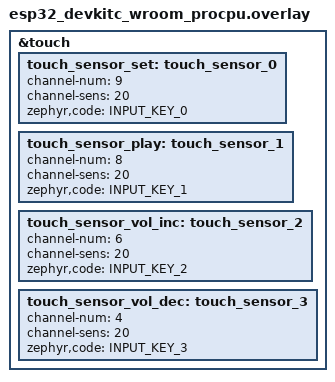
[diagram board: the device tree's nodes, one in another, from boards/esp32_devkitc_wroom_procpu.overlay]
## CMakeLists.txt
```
# SPDX-License-Identifier: Apache-2.0

cmake_minimum_required(VERSION 3.28.0)
find_package(Zephyr REQUIRED HINTS $ENV{ZEPHYR_BASE})
project(input_dump)

target_sources(app PRIVATE src/main.c)

target_sources_ifdef(CONFIG_USB_HOST_STACK app PRIVATE src/usbh_init.c)
```

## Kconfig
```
# Copyright 2023 Google LLC
# SPDX-License-Identifier: Apache-2.0

configdefault INPUT_SHELL
	default y

configdefault INPUT_SHELL_KBD_MATRIX_STATE
	default y

source "Kconfig.zephyr"
```

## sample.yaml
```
sample:
  name: Input Dump
common:
  tags: input
  build_only: true
  integration_platforms:
    - native_sim
tests:
  sample.input.input_dump: {}
  sample.input.input_dump_shell:
    extra_configs:
      - CONFIG_SHELL=y
```

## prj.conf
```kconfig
CONFIG_LOG=y
CONFIG_LOG_MODE_MINIMAL=y

CONFIG_INPUT=y
CONFIG_INPUT_EVENT_DUMP=y
```

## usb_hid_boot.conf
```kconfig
# Copyright (c) 2026 Antmicro <www.antmicro.com>
#
# SPDX-License-Identifier: Apache-2.0

CONFIG_USB_HOST_STACK=y
CONFIG_USBH_HID_BOOT_CLASS=y
CONFIG_USBH_HID_BOOT_INSTANCES_COUNT=1
```

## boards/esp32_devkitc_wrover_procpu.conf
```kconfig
CONFIG_INPUT_ESP32_TOUCH_SENSOR=y
```

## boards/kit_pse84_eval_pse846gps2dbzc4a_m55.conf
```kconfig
# SPDX-FileCopyrightText: Copyright (c) 2026 Infineon Technologies AG,
# SPDX-FileCopyrightText: or an affiliate of Infineon Technologies AG. All rights reserved.
#
# SPDX-License-Identifier: Apache-2.0

CONFIG_INPUT_FT5336_PERIOD_MS=20
CONFIG_INPUT_FT5336_INIT_DELAY_MS=1000
```

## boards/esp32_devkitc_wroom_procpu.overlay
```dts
/*
 * Copyright (c) 2023 Espressif Systems (Shanghai) Co., Ltd.
 *
 * SPDX-License-Identifier: Apache-2.0
 */

#include <zephyr/dt-bindings/input/input-event-codes.h>
#include <zephyr/dt-bindings/input/esp32-touch-sensor-input.h>

&touch {
	status = "okay";

	touch_sensor_set: touch_sensor_0 {
		channel-num = <9>;
		channel-sens = <20>;
		zephyr,code = <INPUT_KEY_0>;
	};

	touch_sensor_play: touch_sensor_1 {
		channel-num = <8>;
		channel-sens = <20>;
		zephyr,code = <INPUT_KEY_1>;
	};

	touch_sensor_vol_inc: touch_sensor_2 {
		channel-num = <6>;
		channel-sens = <20>;
		zephyr,code = <INPUT_KEY_2>;
	};

	touch_sensor_vol_dec: touch_sensor_3 {
		channel-num = <4>;
		channel-sens = <20>;
		zephyr,code = <INPUT_KEY_3>;
	};
};
```

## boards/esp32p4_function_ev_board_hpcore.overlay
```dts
/*
 * Copyright (c) 2026 Espressif Systems (Shanghai) Co., Ltd.
 *
 * SPDX-License-Identifier: Apache-2.0
 */

#include <zephyr/dt-bindings/input/input-event-codes.h>

&touch {
	status = "okay";

	touch_sensor_0 {
		channel-num = <1>;
		channel-sens = <2>;
		zephyr,code = <INPUT_KEY_0>;
	};

	touch_sensor_1 {
		channel-num = <2>;
		channel-sens = <2>;
		zephyr,code = <INPUT_KEY_1>;
	};

	touch_sensor_2 {
		channel-num = <3>;
		channel-sens = <2>;
		zephyr,code = <INPUT_KEY_2>;
	};

	touch_sensor_3 {
		channel-num = <4>;
		channel-sens = <2>;
		zephyr,code = <INPUT_KEY_3>;
	};
};
```

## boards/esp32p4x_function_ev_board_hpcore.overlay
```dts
/*
 * Copyright (c) 2026 Espressif Systems (Shanghai) Co., Ltd.
 *
 * SPDX-License-Identifier: Apache-2.0
 */

#include "esp32p4_function_ev_board_hpcore.overlay"
```

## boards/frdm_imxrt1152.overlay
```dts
/*
 * SPDX-FileCopyrightText: Copyright 2026 NXP
 *
 * SPDX-License-Identifier: Apache-2.0
 */

/*
 * 2x2 key matrix on J11, as in the MCUXpresso SDK kpp example:
 * ROW2 J11-8, ROW3 J11-12, COL2 J11-10, COL3 J11-6.
 */
&pinctrl {
	kpp_default: kpp_default {
		group0 {
			pinmux = <&iomuxc_gpio_ad_30_kpp_row02>,
				 <&iomuxc_gpio_ad_28_kpp_row03>,
				 <&iomuxc_gpio_ad_31_kpp_col02>,
				 <&iomuxc_gpio_ad_29_kpp_col03>;
			drive-strength = "high";
			bias-pull-up;
			slew-rate = "fast";
		};
	};
};

&kpp {
	pinctrl-0 = <&kpp_default>;
	pinctrl-names = "default";
	status = "okay";
};
```

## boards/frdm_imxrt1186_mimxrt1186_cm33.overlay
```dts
/*
 * SPDX-FileCopyrightText: Copyright 2026 NXP
 * SPDX-License-Identifier: Apache-2.0
 *
 * External 2x2 keypad wiring on FRDM-IMXRT1186 Arduino headers:
 *
 *   Keypad term    SoC pin         Arduino socket    KPP signal
 *   -----------    -------------   --------------    ----------
 *   R1             GPIO_EMC_B1_14  J1-10             KPP_ROW0
 *   R2             GPIO_AD_16      J51-4             KPP_ROW5
 *   C1             GPIO_EMC_B1_15  J1-12             KPP_COL0
 *   C2             GPIO_AD_17      J51-6             KPP_COL5
 *
 * Required jumper settings (default is ECAT route, switch to Arduino):
 *   J28 = 2-3  (route GPIO_AD_16 to Arduino J51-4)
 *   J32 = 2-3  (route GPIO_AD_17 to Arduino J51-6)
 */

&pinctrl {
	kpp_default: kpp_default {
		group0 {
			pinmux = <&iomuxc_gpio_ad_16_kpp_row5>,
				 <&iomuxc_gpio_emc_b1_14_kpp_row0>,
				 <&iomuxc_gpio_ad_17_kpp_col5>,
				 <&iomuxc_gpio_emc_b1_15_kpp_col0>;
			drive-strength = "high";
			bias-pull-up;
			slew-rate = "fast";
		};
	};
};

&kpp {
	pinctrl-0 = <&kpp_default>;
	pinctrl-names = "default";
	status = "okay";
};
```

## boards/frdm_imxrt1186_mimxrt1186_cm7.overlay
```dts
/*
 * SPDX-FileCopyrightText: Copyright 2026 NXP
 * SPDX-License-Identifier: Apache-2.0
 */

#include "frdm_imxrt1186_mimxrt1186_cm33.overlay"
```

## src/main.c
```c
/*
 * Copyright 2023 Google LLC
 *
 * SPDX-License-Identifier: Apache-2.0
 */

#include <stdio.h>

int main(void)
{
	printf("Input sample started\n");
	return 0;
}
```

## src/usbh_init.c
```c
/*
 * Copyright (c) 2026 Antmicro <www.antmicro.com>
 *
 * SPDX-License-Identifier: Apache-2.0
 */

#include <zephyr/kernel.h>
#include <zephyr/init.h>
#include <zephyr/device.h>
#include <zephyr/usb/usbh.h>
#include <zephyr/logging/log.h>

LOG_MODULE_REGISTER(init_usb, CONFIG_USBH_LOG_LEVEL);

USBH_CONTROLLER_DEFINE(uhs_ctx, DEVICE_DT_GET(DT_NODELABEL(zephyr_uhc0)));

static int init_usb(void)
{
	int ret;

	ret = usbh_init(&uhs_ctx);
	if (ret) {
		LOG_ERR("Failed to initialize USB host. Error: %d", ret);
		return ret;
	}

	ret = usbh_enable(&uhs_ctx);
	if (ret) {
		LOG_ERR("Failed to enable USB host. Error: %d", ret);
		return ret;
	}

	return 0;
}

SYS_INIT(init_usb, APPLICATION, CONFIG_APPLICATION_INIT_PRIORITY);
```
